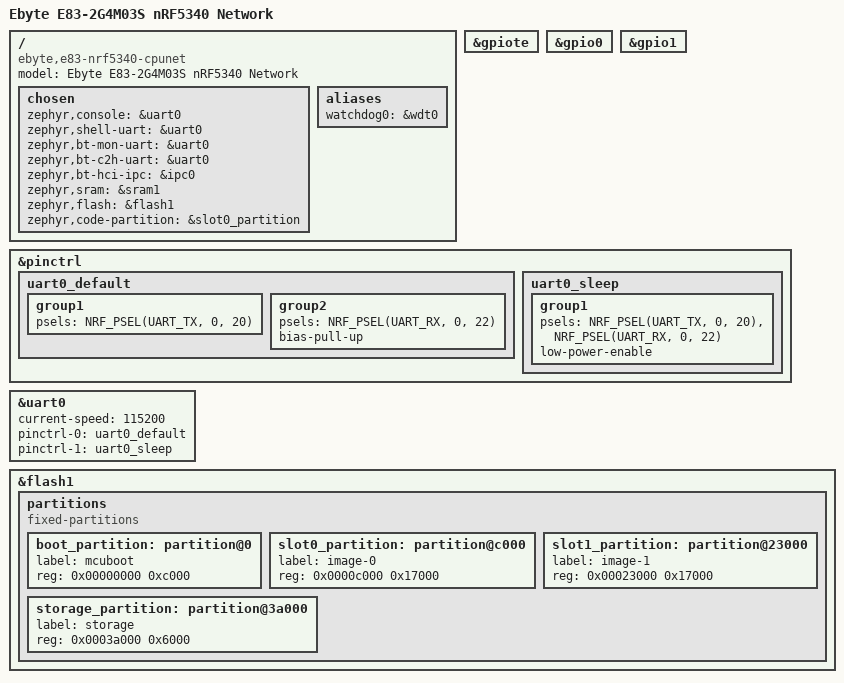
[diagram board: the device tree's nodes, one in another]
/dts-v1/;
#include <nordic/nrf5340_cpunet_qkaa.dtsi>

/ {
	model = "Ebyte E83-2G4M03S nRF5340 Network";
	compatible = "ebyte,e83-nrf5340-cpunet";

	chosen {
		zephyr,console = &uart0;
		zephyr,shell-uart = &uart0;
		zephyr,bt-mon-uart = &uart0;
		zephyr,bt-c2h-uart = &uart0;
		zephyr,bt-hci-ipc = &ipc0;
		zephyr,sram = &sram1;
		zephyr,flash = &flash1;
		zephyr,code-partition = &slot0_partition;
	};

	aliases {
		watchdog0 = &wdt0;
	};
};

&gpiote { status = "okay"; };
&gpio0 { status = "okay"; };
&gpio1 { status = "okay"; };

/* Net core UART0 shares the same CH340X pins as app core (P0.20 TX, P0.22 RX).
 * The app core owns the UART in normal operation; this pinctrl is here so
 * the net-core build can configure the device if it needs logging.
 */
&pinctrl {
	uart0_default: uart0_default {
		group1 {
			psels = <NRF_PSEL(UART_TX, 0, 20)>;
		};
		group2 {
			psels = <NRF_PSEL(UART_RX, 0, 22)>;
			bias-pull-up;
		};
	};
	uart0_sleep: uart0_sleep {
		group1 {
			psels = <NRF_PSEL(UART_TX, 0, 20)>,
				<NRF_PSEL(UART_RX, 0, 22)>;
			low-power-enable;
		};
	};
};

&uart0 {
	status = "okay";
	current-speed = <115200>;
	pinctrl-0 = <&uart0_default>;
	pinctrl-1 = <&uart0_sleep>;
	pinctrl-names = "default", "sleep";
};

&flash1 {
	partitions {
		compatible = "fixed-partitions";
		#address-cells = <1>;
		#size-cells = <1>;

		boot_partition: partition@0 {
			label = "mcuboot";
			reg = <0x00000000 0xc000>;
		};

		slot0_partition: partition@c000 {
			label = "image-0";
			reg = <0x0000c000 0x17000>;
		};

		slot1_partition: partition@23000 {
			label = "image-1";
			reg = <0x00023000 0x17000>;
		};

		storage_partition: partition@3a000 {
			label = "storage";
			reg = <0x0003a000 0x6000>;
		};
	};
};

/* Shared RAM layout between cpuapp and cpunet */
#include <nordic/nrf5340_shared_sram_partition.dtsi>
